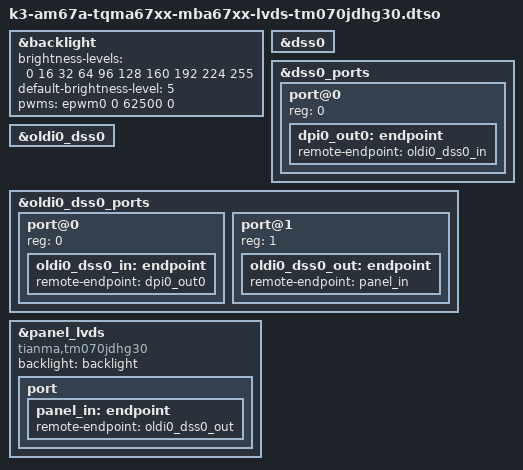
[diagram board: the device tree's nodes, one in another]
// SPDX-License-Identifier: GPL-2.0-only OR MIT
/*
 * Copyright (c) 2023-2024 TQ-Systems GmbH <linux@ew.tq-group.com>, D-82229 Seefeld, Germany.
 * Author: Matthias Schiffer
 */

/dts-v1/;
/plugin/;

#include <dt-bindings/gpio/gpio.h>

&backlight {
	brightness-levels = <0 16 32 64 96 128 160 192 224 255>;
	default-brightness-level = <5>;
	pwms = <&epwm0 0 62500 0>;
	status = "okay";
};

&dss0 {
	status = "okay";
};

&dss0_ports {
	#address-cells = <1>;
	#size-cells = <0>;

	port@0 {
		reg = <0>;

		dpi0_out0: endpoint {
			remote-endpoint = <&oldi0_dss0_in>;
		};
	};
};

&oldi0_dss0 {
	status = "okay";
};

&oldi0_dss0_ports {
	#address-cells = <1>;
	#size-cells = <0>;

	port@0 {
		reg = <0>;

		oldi0_dss0_in: endpoint {
			remote-endpoint = <&dpi0_out0>;
		};
	};

	port@1 {
		reg = <1>;

		oldi0_dss0_out: endpoint {
			remote-endpoint = <&panel_in>;
		};
	};
};

&panel_lvds {
	compatible = "tianma,tm070jdhg30";
	backlight = <&backlight>;
	status = "okay";

	port {
		panel_in: endpoint {
			remote-endpoint = <&oldi0_dss0_out>;
		};
	};
};
